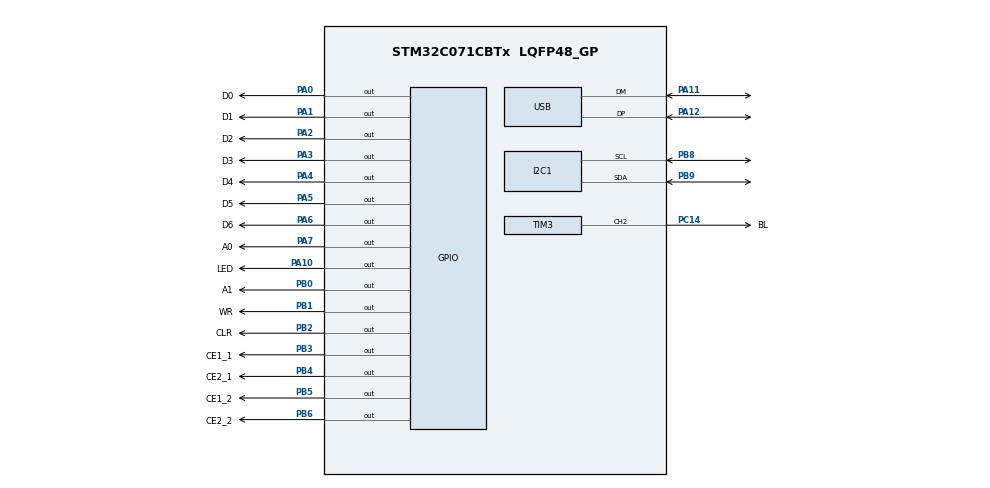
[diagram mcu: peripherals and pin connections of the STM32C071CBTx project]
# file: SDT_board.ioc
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I2C1.Timing=0x00402D41
Mcu.Family=STM32C0
Mcu.Name=STM32C071CBTx
Mcu.Package=LQFP48_GP
NVIC.USB_DRD_FS_IRQn=true\:0\:0\:false\:false\:true\:true\:true\:true
PA0.GPIO_Label=D0
PA0.Signal=GPIO_Output
PA1.GPIO_Label=D1
PA1.Signal=GPIO_Output
PA10.GPIO_Label=LED
PA10.Signal=GPIO_Output
PA11\ [PA9].Mode=Device
PA11\ [PA9].Signal=USB_DM
PA12\ [PA10].Mode=Device
PA12\ [PA10].Signal=USB_DP
PA13.Mode=Serial_Wire
PA13.Signal=DEBUG_SWDIO
PA14-BOOT0.Mode=Serial_Wire
PA14-BOOT0.Signal=DEBUG_SWCLK
PA2.GPIO_Label=D2
PA2.Signal=GPIO_Output
PA3.GPIO_Label=D3
PA3.Signal=GPIO_Output
PA4.GPIO_Label=D4
PA4.Signal=GPIO_Output
PA5.GPIO_Label=D5
PA5.Signal=GPIO_Output
PA6.GPIO_Label=D6
PA6.Signal=GPIO_Output
PA7.GPIO_Label=A0
PA7.Signal=GPIO_Output
PB0.GPIO_Label=A1
PB0.Signal=GPIO_Output
PB1.GPIO_Label=WR
PB1.Signal=GPIO_Output
PB2.GPIO_Label=CLR
PB2.Signal=GPIO_Output
PB3.GPIO_Label=CE1_1
PB3.Signal=GPIO_Output
PB4.GPIO_Label=CE2_1
PB4.Signal=GPIO_Output
PB5.GPIO_Label=CE1_2
PB5.Signal=GPIO_Output
PB6.GPIO_Label=CE2_2
PB6.Signal=GPIO_Output
PB8.Mode=I2C
PB8.Signal=I2C1_SCL
PB9.Mode=I2C
PB9.Signal=I2C1_SDA
PC14-OSCX_IN(PC14).GPIO_Label=BL
PC14-OSCX_IN(PC14).Signal=S_TIM3_CH2
ProjectManager.HeapSize=0x200
ProjectManager.StackSize=0x400
ProjectManager.TargetToolchain=STM32CubeIDE
RCC.ADCFreq_Value=12000000
RCC.AHBFreq_Value=12000000
RCC.CortexFreq_Value=12000000
RCC.EXTERNAL_CLOCK_VALUE=12288000
RCC.HCLKFreq_Value=12000000
RCC.HSE_VALUE=8000000
RCC.HSI48_VALUE=48000000
RCC.HSI_VALUE=48000000
RCC.I2C1CLockSelection=RCC_I2C1CLKSOURCE_SYSCLK
RCC.LSE_VALUE=32768
RCC.SYSCLKFreq_VALUE=12000000
RCC.SYSCLKSource=RCC_SYSCLKSOURCE_HSIUSB48
RCC.SYSDIV=RCC_SYSCLK_DIV4
SH.S_TIM3_CH2.0=TIM3_CH2,PWM Generation2 CH2
TIM3.Channel-PWM\ Generation2\ CH2=TIM_CHANNEL_2
TIM3.Period=255
USB.VirtualMode=Device_Only
VP_TIM3_VS_ClockSourceINT.Mode=Internal
board=custom

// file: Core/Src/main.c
/* USER CODE BEGIN Header */
/**
  ******************************************************************************
  * @file           : main.c
  * @brief          : Main program body
  ******************************************************************************
  * @attention
  *
  * Copyright (c) 2026 STMicroelectronics.
  * All rights reserved.
  *
  * This software is licensed under terms that can be found in the LICENSE file
  * in the root directory of this software component.
  * If no LICENSE file comes with this software, it is provided AS-IS.
  *
  ******************************************************************************
  */
/* USER CODE END Header */
#include "main.h"

/* USER CODE BEGIN Includes */
#include <mainApp.h>
/* USER CODE END Includes */

I2C_HandleTypeDef hi2c1;

TIM_HandleTypeDef htim3;

PCD_HandleTypeDef hpcd_USB_DRD_FS;

void SystemClock_Config(void);
static void MX_GPIO_Init(void);
static void MX_I2C1_Init(void);
static void MX_TIM3_Init(void);
static void MX_USB_PCD_Init(void);

int main(void)
{

  /* MCU Configuration--------------------------------------------------------*/

  /* Reset of all peripherals, Initializes the Flash interface and the Systick. */
  HAL_Init();

  /* Configure the system clock */
  SystemClock_Config();

  /* Initialize all configured peripherals */
  MX_GPIO_Init();
  MX_I2C1_Init();
  MX_TIM3_Init();
  MX_USB_PCD_Init();
  /* USER CODE BEGIN 2 */
  AppInit();
  /* USER CODE END 2 */

  /* Infinite loop */
  while (1)
  {
	  AppMain();
  }
}

void SystemClock_Config(void)
{
  RCC_OscInitTypeDef RCC_OscInitStruct = {0};
  RCC_ClkInitTypeDef RCC_ClkInitStruct = {0};

  __HAL_FLASH_SET_LATENCY(FLASH_LATENCY_0);

  /** Initializes the RCC Oscillators according to the specified parameters
  * in the RCC_OscInitTypeDef structure.
  */
  RCC_OscInitStruct.OscillatorType = RCC_OSCILLATORTYPE_HSI48;
  RCC_OscInitStruct.HSI48State = RCC_HSI48_ON;

  if (HAL_RCC_OscConfig(&RCC_OscInitStruct) != HAL_OK)
  {
    Error_Handler();
  }

  /** Initializes the CPU, AHB and APB buses clocks
  */
  RCC_ClkInitStruct.ClockType = RCC_CLOCKTYPE_HCLK|RCC_CLOCKTYPE_SYSCLK
                              |RCC_CLOCKTYPE_PCLK1;
  RCC_ClkInitStruct.SYSCLKSource = RCC_SYSCLKSOURCE_HSIUSB48;
  RCC_ClkInitStruct.SYSCLKDivider = RCC_SYSCLK_DIV4;
  RCC_ClkInitStruct.AHBCLKDivider = RCC_HCLK_DIV1;
  RCC_ClkInitStruct.APB1CLKDivider = RCC_APB1_DIV1;

  if (HAL_RCC_ClockConfig(&RCC_ClkInitStruct, FLASH_LATENCY_0) != HAL_OK)
  {
    Error_Handler();
  }
}

static void MX_I2C1_Init(void)
{

  hi2c1.Instance = I2C1;
  hi2c1.Init.Timing = 0x00402D41;
  hi2c1.Init.OwnAddress1 = 0;
  hi2c1.Init.AddressingMode = I2C_ADDRESSINGMODE_7BIT;
  hi2c1.Init.DualAddressMode = I2C_DUALADDRESS_DISABLE;
  hi2c1.Init.OwnAddress2 = 0;
  hi2c1.Init.OwnAddress2Masks = I2C_OA2_NOMASK;
  hi2c1.Init.GeneralCallMode = I2C_GENERALCALL_DISABLE;
  hi2c1.Init.NoStretchMode = I2C_NOSTRETCH_DISABLE;
  if (HAL_I2C_Init(&hi2c1) != HAL_OK)
  {
    Error_Handler();
  }

  /** Configure Analogue filter
  */
  if (HAL_I2CEx_ConfigAnalogFilter(&hi2c1, I2C_ANALOGFILTER_ENABLE) != HAL_OK)
  {
    Error_Handler();
  }

  /** Configure Digital filter
  */
  if (HAL_I2CEx_ConfigDigitalFilter(&hi2c1, 0) != HAL_OK)
  {
    Error_Handler();
  }

}

static void MX_TIM3_Init(void)
{

  TIM_ClockConfigTypeDef sClockSourceConfig = {0};
  TIM_MasterConfigTypeDef sMasterConfig = {0};
  TIM_OC_InitTypeDef sConfigOC = {0};

  htim3.Instance = TIM3;
  htim3.Init.Prescaler = 0;
  htim3.Init.CounterMode = TIM_COUNTERMODE_UP;
  htim3.Init.Period = 255;
  htim3.Init.ClockDivision = TIM_CLOCKDIVISION_DIV1;
  htim3.Init.AutoReloadPreload = TIM_AUTORELOAD_PRELOAD_DISABLE;
  if (HAL_TIM_Base_Init(&htim3) != HAL_OK)
  {
    Error_Handler();
  }
  sClockSourceConfig.ClockSource = TIM_CLOCKSOURCE_INTERNAL;
  if (HAL_TIM_ConfigClockSource(&htim3, &sClockSourceConfig) != HAL_OK)
  {
    Error_Handler();
  }
  if (HAL_TIM_PWM_Init(&htim3) != HAL_OK)
  {
    Error_Handler();
  }
  sMasterConfig.MasterOutputTrigger = TIM_TRGO_RESET;
  sMasterConfig.MasterSlaveMode = TIM_MASTERSLAVEMODE_DISABLE;
  if (HAL_TIMEx_MasterConfigSynchronization(&htim3, &sMasterConfig) != HAL_OK)
  {
    Error_Handler();
  }
  sConfigOC.OCMode = TIM_OCMODE_PWM1;
  sConfigOC.Pulse = 0;
  sConfigOC.OCPolarity = TIM_OCPOLARITY_HIGH;
  sConfigOC.OCFastMode = TIM_OCFAST_DISABLE;
  if (HAL_TIM_PWM_ConfigChannel(&htim3, &sConfigOC, TIM_CHANNEL_2) != HAL_OK)
  {
    Error_Handler();
  }
  HAL_TIM_MspPostInit(&htim3);

}

static void MX_USB_PCD_Init(void)
{

  hpcd_USB_DRD_FS.Instance = USB_DRD_FS;
  hpcd_USB_DRD_FS.Init.dev_endpoints = 8;
  hpcd_USB_DRD_FS.Init.speed = USBD_FS_SPEED;
  hpcd_USB_DRD_FS.Init.phy_itface = PCD_PHY_EMBEDDED;
  hpcd_USB_DRD_FS.Init.Sof_enable = DISABLE;
  hpcd_USB_DRD_FS.Init.low_power_enable = DISABLE;
  hpcd_USB_DRD_FS.Init.lpm_enable = DISABLE;
  hpcd_USB_DRD_FS.Init.battery_charging_enable = DISABLE;
  hpcd_USB_DRD_FS.Init.vbus_sensing_enable = DISABLE;
  hpcd_USB_DRD_FS.Init.bulk_doublebuffer_enable = DISABLE;
  hpcd_USB_DRD_FS.Init.iso_singlebuffer_enable = DISABLE;
  if (HAL_PCD_Init(&hpcd_USB_DRD_FS) != HAL_OK)
  {
    Error_Handler();
  }

}

static void MX_GPIO_Init(void)
{
  GPIO_InitTypeDef GPIO_InitStruct = {0};

  /* GPIO Ports Clock Enable */
  __HAL_RCC_GPIOC_CLK_ENABLE();
  __HAL_RCC_GPIOA_CLK_ENABLE();
  __HAL_RCC_GPIOB_CLK_ENABLE();

  /*Configure GPIO pin Output Level */
  HAL_GPIO_WritePin(GPIOA, D0_Pin|D1_Pin|D2_Pin|D3_Pin
                          |D4_Pin|D5_Pin|D6_Pin|A0_Pin
                          |LED_Pin, GPIO_PIN_RESET);

  /*Configure GPIO pin Output Level */
  HAL_GPIO_WritePin(GPIOB, A1_Pin|WR_Pin|CLR_Pin|CE1_1_Pin
                          |CE2_1_Pin|CE1_2_Pin|CE2_2_Pin, GPIO_PIN_RESET);

  /*Configure GPIO pins : D0_Pin D1_Pin D2_Pin D3_Pin
                           D4_Pin D5_Pin D6_Pin A0_Pin
                           LED_Pin */
  GPIO_InitStruct.Pin = D0_Pin|D1_Pin|D2_Pin|D3_Pin
                          |D4_Pin|D5_Pin|D6_Pin|A0_Pin
                          |LED_Pin;
  GPIO_InitStruct.Mode = GPIO_MODE_OUTPUT_PP;
  GPIO_InitStruct.Pull = GPIO_NOPULL;
  GPIO_InitStruct.Speed = GPIO_SPEED_FREQ_LOW;
  HAL_GPIO_Init(GPIOA, &GPIO_InitStruct);

  /*Configure GPIO pins : A1_Pin WR_Pin CLR_Pin CE1_1_Pin
                           CE2_1_Pin CE1_2_Pin CE2_2_Pin */
  GPIO_InitStruct.Pin = A1_Pin|WR_Pin|CLR_Pin|CE1_1_Pin
                          |CE2_1_Pin|CE1_2_Pin|CE2_2_Pin;
  GPIO_InitStruct.Mode = GPIO_MODE_OUTPUT_PP;
  GPIO_InitStruct.Pull = GPIO_NOPULL;
  GPIO_InitStruct.Speed = GPIO_SPEED_FREQ_LOW;
  HAL_GPIO_Init(GPIOB, &GPIO_InitStruct);

}

void Error_Handler(void)
{
  __disable_irq();
  while (1)
  {
  }
}
